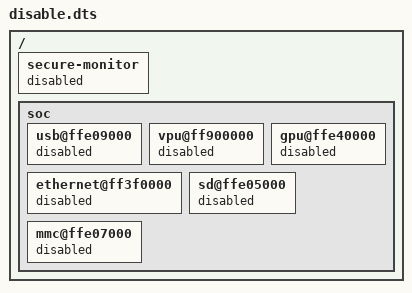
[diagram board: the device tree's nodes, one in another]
/ {
    secure-monitor {
		status = "disabled";
	};

    soc {
        usb@ffe09000 {
            status = "disabled";
        };
        
        vpu@ff900000 {
            status = "disabled";
        };

        gpu@ffe40000 {
            status = "disabled";
        };

        /delete-node/ bus@ff600000;
        /delete-node/ bus@ffd00000;
        /delete-node/ bus@ff800000;

        ethernet@ff3f0000 {
            status = "disabled";
        };

        sd@ffe05000 {
            status = "disabled";
        };

        mmc@ffe07000 {
            status = "disabled";
        };
    };
};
